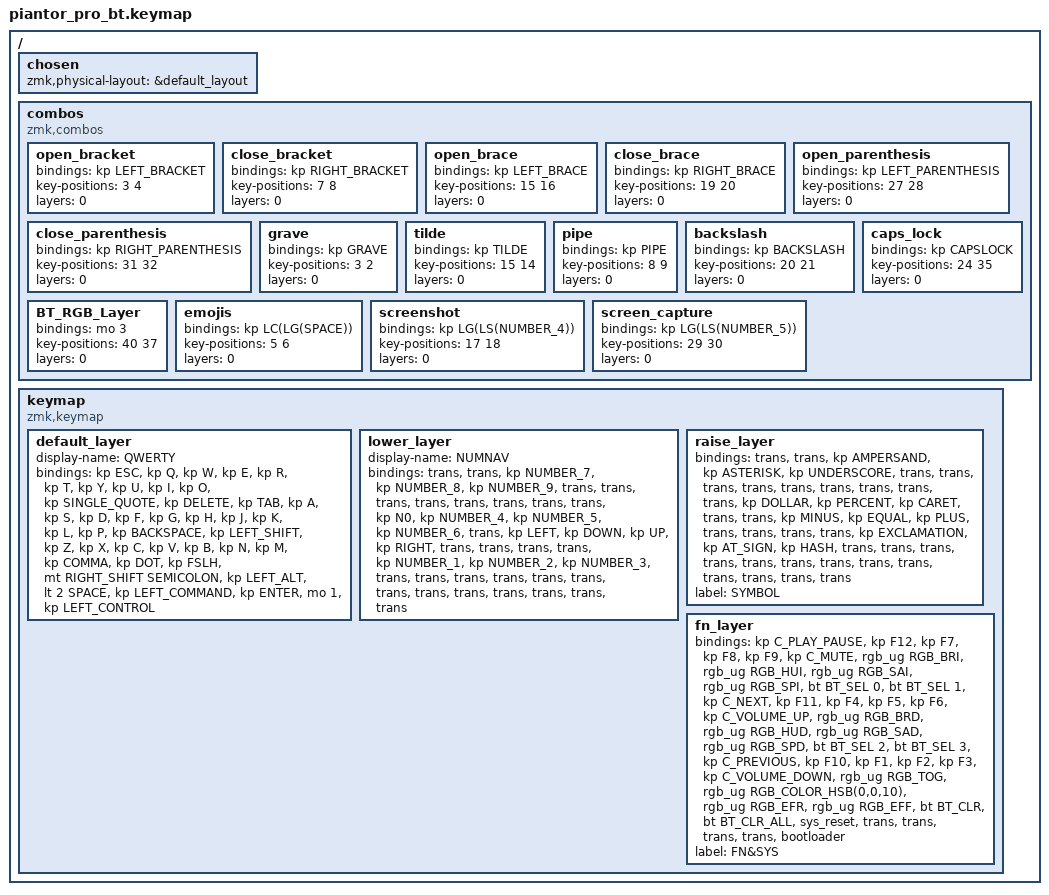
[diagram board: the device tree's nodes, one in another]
/*
 * Copyright (c) 2020 The ZMK Contributors
 *
 * SPDX-License-Identifier: MIT
 */

#include <behaviors.dtsi>
#include <dt-bindings/zmk/bt.h>
#include <dt-bindings/zmk/keys.h>
#include <dt-bindings/zmk/rgb.h>

/ {
    chosen { zmk,physical-layout = &default_layout; };
};

/ {
    combos {
        compatible = "zmk,combos";

        open_bracket {
            bindings = <&kp LEFT_BRACKET>;
            key-positions = <3 4>;
            layers = <0>;
        };

        close_bracket {
            bindings = <&kp RIGHT_BRACKET>;
            key-positions = <7 8>;
            layers = <0>;
        };

        open_brace {
            bindings = <&kp LEFT_BRACE>;
            key-positions = <15 16>;
            layers = <0>;
        };

        close_brace {
            bindings = <&kp RIGHT_BRACE>;
            key-positions = <19 20>;
            layers = <0>;
        };

        open_parenthesis {
            bindings = <&kp LEFT_PARENTHESIS>;
            key-positions = <27 28>;
            layers = <0>;
        };

        close_parenthesis {
            bindings = <&kp RIGHT_PARENTHESIS>;
            key-positions = <31 32>;
            layers = <0>;
        };

        grave {
            bindings = <&kp GRAVE>;
            key-positions = <3 2>;
            layers = <0>;
        };

        tilde {
            bindings = <&kp TILDE>;
            key-positions = <15 14>;
            layers = <0>;
        };

        pipe {
            bindings = <&kp PIPE>;
            key-positions = <8 9>;
            layers = <0>;
        };

        backslash {
            bindings = <&kp BACKSLASH>;
            key-positions = <20 21>;
            layers = <0>;
        };

        caps_lock {
            bindings = <&kp CAPSLOCK>;
            key-positions = <24 35>;
            layers = <0>;
        };

        BT_RGB_Layer {
            bindings = <&mo 3>;
            key-positions = <40 37>;
            layers = <0>;
        };

        emojis {
            bindings = <&kp LC(LG(SPACE))>;
            key-positions = <5 6>;
            layers = <0>;
        };

        screenshot {
            bindings = <&kp LG(LS(NUMBER_4))>;
            key-positions = <17 18>;
            layers = <0>;
        };

        screen_capture {
            bindings = <&kp LG(LS(NUMBER_5))>;
            key-positions = <29 30>;
            layers = <0>;
        };
    };

    keymap {
        compatible = "zmk,keymap";

        default_layer {
            display-name = "QWERTY";

            // --------------------------------------------------------------------------------
            // |  TAB |  Q  |  W  |  E  |  R  |  T  |  Y  |  U   |  I  |  O  |  P  | BSPC |
            // | CTRL |  A  |  S  |  D  |  F  |  G  |  H  |  J   |  K  |  L  |  ;  |  '   |
            // | SHFT |  Z  |  X  |  C  |  V  |  B  |  N  |  M   |  ,  |  .  |  /  | ESC  |
            //                    | GUI | LWR | SPC | ENT | RSE  | ALT |

            bindings = <
&kp ESC  &kp Q  &kp W  &kp E  &kp R  &kp T  &kp Y  &kp U  &kp I  &kp O  &kp SINGLE_QUOTE  &kp DELETE  &kp TAB  &kp A  &kp S  &kp D  &kp F  &kp G  &kp H  &kp J  &kp K  &kp L  &kp P  &kp BACKSPACE  &kp LEFT_SHIFT  &kp Z  &kp X  &kp C  &kp V  &kp B  &kp N  &kp M  &kp COMMA  &kp DOT  &kp FSLH  &mt RIGHT_SHIFT SEMICOLON  &kp LEFT_ALT  &lt 2 SPACE  &kp LEFT_COMMAND  &kp ENTER  &mo 1  &kp LEFT_CONTROL
            >;
        };

        lower_layer {
            display-name = "NUMNAV";

            // -----------------------------------------------------------------------------------------
            // |  TAB |  1  |  2  |  3  |  4  |  5    |  6  |  7  |  8  |  9  |  0  | BSPC |
            // | CTRL | BT1 | BT2 | BT3 | BT4 | BT5   | LFT | DWN |  UP | RGT |     |      |
            // | SHFT | BTCR| RGB | RST | BOOT| Unlock|     |     |     |     |     |      |
            //                    | GUI |     | SPC   | ENT |     | ALT |

            bindings = <
&trans  &trans  &kp NUMBER_7  &kp NUMBER_8  &kp NUMBER_9  &trans  &trans  &trans  &trans  &trans  &trans  &trans  &trans  &kp N0  &kp NUMBER_4  &kp NUMBER_5  &kp NUMBER_6  &trans  &kp LEFT  &kp DOWN  &kp UP  &kp RIGHT  &trans  &trans  &trans  &trans  &kp NUMBER_1  &kp NUMBER_2  &kp NUMBER_3  &trans  &trans  &trans  &trans  &trans  &trans  &trans  &trans  &trans  &trans  &trans  &trans  &trans
            >;
        };

        raise_layer {
            bindings = <
&trans  &trans  &kp AMPERSAND  &kp ASTERISK  &kp UNDERSCORE  &trans  &trans  &trans  &trans  &trans  &trans  &trans  &trans  &trans  &kp DOLLAR  &kp PERCENT  &kp CARET  &trans  &trans  &kp MINUS  &kp EQUAL  &kp PLUS  &trans  &trans  &trans  &trans  &kp EXCLAMATION  &kp AT_SIGN  &kp HASH  &trans  &trans  &trans  &trans  &trans  &trans  &trans  &trans  &trans  &trans  &trans  &trans  &trans
            >;

            label = "SYMBOL";
        };

        fn_layer {
            bindings = <
&kp C_PLAY_PAUSE  &kp F12  &kp F7  &kp F8  &kp F9  &kp C_MUTE  &rgb_ug RGB_BRI  &rgb_ug RGB_HUI  &rgb_ug RGB_SAI  &rgb_ug RGB_SPI  &bt BT_SEL 0  &bt BT_SEL 1  &kp C_NEXT  &kp F11  &kp F4  &kp F5  &kp F6  &kp C_VOLUME_UP  &rgb_ug RGB_BRD  &rgb_ug RGB_HUD  &rgb_ug RGB_SAD  &rgb_ug RGB_SPD  &bt BT_SEL 2  &bt BT_SEL 3  &kp C_PREVIOUS  &kp F10  &kp F1  &kp F2  &kp F3  &kp C_VOLUME_DOWN  &rgb_ug RGB_TOG  &rgb_ug RGB_COLOR_HSB(0,0,10)  &rgb_ug RGB_EFR  &rgb_ug RGB_EFF  &bt BT_CLR  &bt BT_CLR_ALL  &sys_reset  &trans  &trans  &trans  &trans  &bootloader
            >;

            label = "FN&SYS";
        };
    };
};
